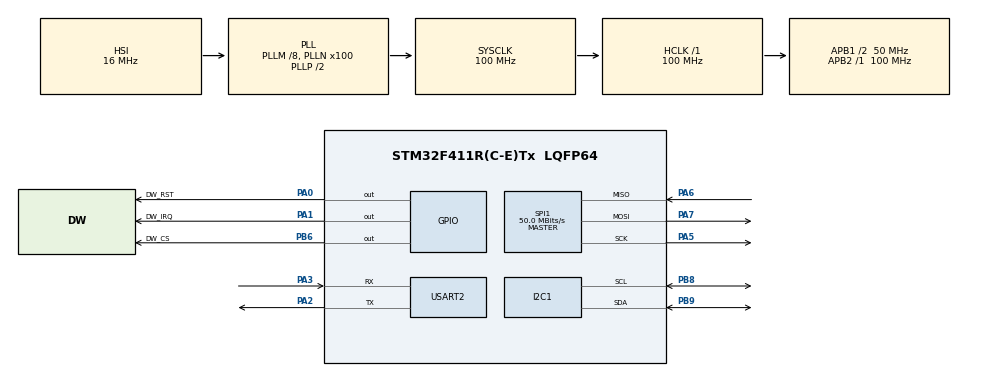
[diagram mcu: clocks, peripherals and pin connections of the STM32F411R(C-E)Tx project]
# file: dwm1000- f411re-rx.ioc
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I2C1.I2C_Mode=I2C_Fast
Mcu.Family=STM32F4
Mcu.Name=STM32F411R(C-E)Tx
Mcu.Package=LQFP64
NVIC.PriorityGroup=NVIC_PRIORITYGROUP_4
NVIC.SPI1_IRQn=true\:0\:0\:false\:false\:true\:true\:true
PA0-WKUP.GPIO_Label=DW_RST
PA0-WKUP.Signal=GPIO_Output
PA1.GPIO_Label=DW_IRQ
PA1.Signal=GPIO_Output
PA2.Mode=Asynchronous
PA2.Signal=USART2_TX
PA3.Mode=Asynchronous
PA3.Signal=USART2_RX
PA5.Mode=Full_Duplex_Master
PA5.Signal=SPI1_SCK
PA6.Mode=Full_Duplex_Master
PA6.Signal=SPI1_MISO
PA7.Mode=Full_Duplex_Master
PA7.Signal=SPI1_MOSI
PB6.GPIO_Label=DW_CS
PB6.Signal=GPIO_Output
PB8.Mode=I2C
PB8.Signal=I2C1_SCL
PB9.Mode=I2C
PB9.Signal=I2C1_SDA
PC14-OSC32_IN.Mode=LSE-External-Oscillator
PC14-OSC32_IN.Signal=RCC_OSC32_IN
PC15-OSC32_OUT.Mode=LSE-External-Oscillator
PC15-OSC32_OUT.Signal=RCC_OSC32_OUT
PH0\ -\ OSC_IN.Mode=HSE-External-Oscillator
PH0\ -\ OSC_IN.Signal=RCC_OSC_IN
PH1\ -\ OSC_OUT.Mode=HSE-External-Oscillator
PH1\ -\ OSC_OUT.Signal=RCC_OSC_OUT
ProjectManager.HeapSize=0x200
ProjectManager.StackSize=0x400
ProjectManager.TargetToolchain=STM32CubeIDE
RCC.48MHZClocksFreq_Value=50000000
RCC.AHBFreq_Value=100000000
RCC.APB1CLKDivider=RCC_HCLK_DIV2
RCC.APB1Freq_Value=50000000
RCC.APB1TimFreq_Value=100000000
RCC.APB2Freq_Value=100000000
RCC.APB2TimFreq_Value=100000000
RCC.CortexFreq_Value=100000000
RCC.HCLKFreq_Value=100000000
RCC.HSE_VALUE=25000000
RCC.HSI_VALUE=16000000
RCC.PLLM=8
RCC.PLLN=100
RCC.SYSCLKFreq_VALUE=100000000
RCC.SYSCLKSource=RCC_SYSCLKSOURCE_PLLCLK
RCC.VCOOutputFreq_Value=200000000
SPI1.CalculateBaudRate=50.0 MBits/s
SPI1.Direction=SPI_DIRECTION_2LINES
SPI1.Mode=SPI_MODE_MASTER
SPI1.VirtualType=VM_MASTER
USART2.VirtualMode=VM_ASYNC
board=custom

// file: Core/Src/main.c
/* USER CODE BEGIN Header */
/**
  ******************************************************************************
  * @file           : main.c
  * @brief          : Main program body
  ******************************************************************************
  * @attention
  *
  * <h2><center>&copy; Copyright (c) 2023 STMicroelectronics.
  * All rights reserved.</center></h2>
  *
  * This software component is licensed by ST under BSD 3-Clause license,
  * the "License"; You may not use this file except in compliance with the
  * License. You may obtain a copy of the License at:
  *                        opensource.org/licenses/BSD-3-Clause
  *
  ******************************************************************************
  */
/* USER CODE END Header */
#include "main.h"
#include "i2c.h"
#include "spi.h"
#include "usart.h"
#include "gpio.h"
#include "ssd1306.h"

/* USER CODE BEGIN PTD */
extern int dw_main(void);
/* USER CODE END PTD */

void SystemClock_Config(void);

int main(void)
{

  /* MCU Configuration--------------------------------------------------------*/

  /* Reset of all peripherals, Initializes the Flash interface and the Systick. */
  HAL_Init();

  /* Configure the system clock */
  SystemClock_Config();

  /* Initialize all configured peripherals */
  MX_GPIO_Init();
  MX_SPI1_Init();
  MX_USART2_UART_Init();
  MX_I2C1_Init();
  /* USER CODE BEGIN 2 */
  setup_DW1000RSTnIRQ(0);
  SSD1306_Init();
    dw_main();
  /* USER CODE END 2 */

  /* Infinite loop */
  while (1)
  {

  }
}

void SystemClock_Config(void)
{
  RCC_OscInitTypeDef RCC_OscInitStruct = {0};
  RCC_ClkInitTypeDef RCC_ClkInitStruct = {0};

  /** Configure the main internal regulator output voltage
  */
  __HAL_RCC_PWR_CLK_ENABLE();
  __HAL_PWR_VOLTAGESCALING_CONFIG(PWR_REGULATOR_VOLTAGE_SCALE1);
  /** Initializes the RCC Oscillators according to the specified parameters
  * in the RCC_OscInitTypeDef structure.
  */
  RCC_OscInitStruct.OscillatorType = RCC_OSCILLATORTYPE_HSI;
  RCC_OscInitStruct.HSIState = RCC_HSI_ON;
  RCC_OscInitStruct.HSICalibrationValue = RCC_HSICALIBRATION_DEFAULT;
  RCC_OscInitStruct.PLL.PLLState = RCC_PLL_ON;
  RCC_OscInitStruct.PLL.PLLSource = RCC_PLLSOURCE_HSI;
  RCC_OscInitStruct.PLL.PLLM = 8;
  RCC_OscInitStruct.PLL.PLLN = 100;
  RCC_OscInitStruct.PLL.PLLP = RCC_PLLP_DIV2;
  RCC_OscInitStruct.PLL.PLLQ = 4;
  if (HAL_RCC_OscConfig(&RCC_OscInitStruct) != HAL_OK)
  {
    Error_Handler();
  }
  /** Initializes the CPU, AHB and APB buses clocks
  */
  RCC_ClkInitStruct.ClockType = RCC_CLOCKTYPE_HCLK|RCC_CLOCKTYPE_SYSCLK
                              |RCC_CLOCKTYPE_PCLK1|RCC_CLOCKTYPE_PCLK2;
  RCC_ClkInitStruct.SYSCLKSource = RCC_SYSCLKSOURCE_PLLCLK;
  RCC_ClkInitStruct.AHBCLKDivider = RCC_SYSCLK_DIV1;
  RCC_ClkInitStruct.APB1CLKDivider = RCC_HCLK_DIV2;
  RCC_ClkInitStruct.APB2CLKDivider = RCC_HCLK_DIV1;

  if (HAL_RCC_ClockConfig(&RCC_ClkInitStruct, FLASH_LATENCY_3) != HAL_OK)
  {
    Error_Handler();
  }
}

void Error_Handler(void)
{
  __disable_irq();
  while (1)
  {
  }
}

/************************ (C) COPYRIGHT STMicroelectronics *****END OF FILE****/
